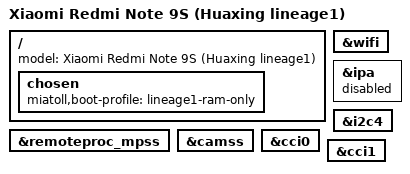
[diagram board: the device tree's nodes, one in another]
// SPDX-License-Identifier: GPL-2.0
// LineageOS SD-card boot: gpu1 DT (display, touch, USB, audio, Adreno) plus
// the modem remoteproc and Wi-Fi. Android finds its partitions on the SM32G
// microSD only. The internal UFS is probed only so that rmtfs can read the
// modem EFS partitions; the vendor init marks every UFS block device
// read-only and nothing mounts them. IPA (modem data) stays disabled.
#include "sm7125-xiaomi-curtana-gpu1.dts"

/ {
	model = "Xiaomi Redmi Note 9S (Huaxing lineage1)";
	chosen {
		miatoll,boot-profile = "lineage1-ram-only";
	};
};

&remoteproc_mpss { status = "okay"; };
&wifi { status = "okay"; };
&ipa { status = "disabled"; };
/* Haptics (AW8624 or DRV2624) on the QUP0 I2C bus. */
&i2c4 { status = "okay"; };
/* Cameras: CAMSS with the sensors on the two CCI controllers. */
&camss { status = "okay"; };
&cci0 { status = "okay"; };
&cci1 { status = "okay"; };
